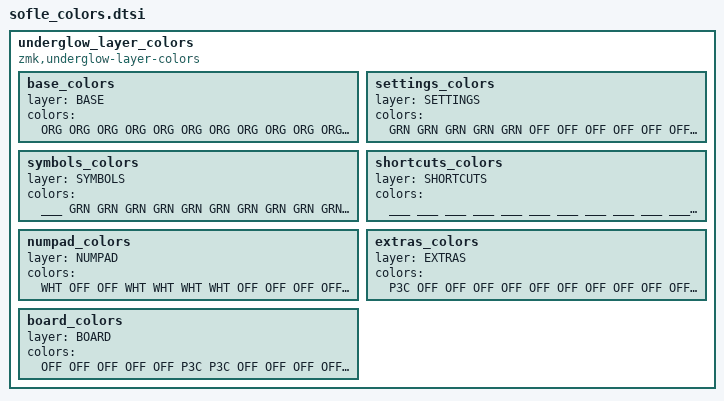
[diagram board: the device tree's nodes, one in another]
/*
 * Inclus dans sofle.keymap (à l'intérieur du nœud racine / { ... }).
 * Les noms de layers (BASE, SETTINGS...) sont définis dans sofle.keymap.
 */

/*
 * Couleurs par touche pour l'effet "couleurs par layer" (effet 4, fork ZMK
 * TheOnlyOneAkira/zmk branche sofle-layer-colors).
 * - Même disposition que les bindings du keymap (60 positions ; les deux
 *   emplacements des clics d'encodeur n'ont pas de LED, la valeur est ignorée).
 * - Le layer actif le plus haut qui définit une couleur l'emporte ;
 *   ___ (RGB_TRANS) laisse voir la couleur du layer en dessous.
 * - Une touche sans couleur sur aucun layer actif reste éteinte.
 * - Couleurs en 0xRRGGBB ; la luminosité globale (RGB_BRI / RGB_BRD) s'applique.
 *   La teinte (RGB_HUI, &rgb_p1...) n'a pas d'effet sur cet effet.
 */
#define ___ RGB_TRANS
#define OFF 0x000000
#define WHT 0xFFFFFF
#define RED 0xFF0000
#define GRN 0x00FF00
#define BLU 0x0000FF
#define CYN 0x00FFFF
#define PUR 0x8000FF
#define ORG 0xFF6000
#define YEL 0xFFC000
// Aperçu des presets &rgb_p1 ... &rgb_p5 (layer NUMPAD)
#define P1C 0xFF2A00
#define P2C 0xFFD400
#define P3C 0x00FFAA
#define P4C 0xD400FF
#define P5C 0x330800

    underglow_layer_colors {
        compatible = "zmk,underglow-layer-colors";

        base_colors {
            layer = <BASE>;
            colors = <
ORG ORG ORG ORG ORG ORG         ORG ORG ORG ORG ORG ORG
ORG ORG ORG ORG ORG ORG         ORG ORG ORG ORG ORG ORG
ORG ORG ORG ORG ORG ORG         ORG ORG ORG ORG ORG ORG
ORG ORG ORG ORG ORG ORG ___ ___ ORG ORG ORG ORG ORG ORG
        ORG ORG CYN ORG ORG ORG ORG GRN ORG ORG
            >;
        };

        // Bleu : sélection BT, cyan : déconnexion BT, rouge : BT_CLR, blanc : médias
        settings_colors {
            layer = <SETTINGS>;
            colors = <
GRN GRN GRN GRN GRN OFF         OFF OFF OFF OFF OFF OFF
ORG ORG ORG ORG ORG OFF         OFF OFF P2C OFF OFF OFF
___ OFF OFF OFF OFF OFF         OFF P2C P2C P2C OFF OFF
RED OFF OFF OFF OFF OFF OFF OFF OFF OFF OFF OFF ___ ___
        ___ ___ ___ ___ ___ ___ ___ ___ ___ ___
            >;
        };

        // Vert : F1-F12 et symboles, violet : accès au layer EXTRAS
        symbols_colors {
            layer = <SYMBOLS>;
            colors = <
___ GRN GRN GRN GRN GRN         GRN GRN GRN GRN GRN GRN
___ OFF OFF OFF OFF OFF         GRN GRN GRN GRN GRN GRN
___ OFF OFF OFF OFF OFF         GRN GRN GRN GRN GRN ___
___ OFF OFF GRN GRN GRN ___ ___ GRN GRN GRN OFF GRN ___
        OFF OFF P4C OFF ___ ___ ___ ___ CYN ___
            >;
        };

        // Jaune : raccourcis et navigation, blanc : flèches, violet : accès au layer EXTRAS
        shortcuts_colors {
            layer = <SHORTCUTS>;
            colors = <
___ ___ ___ ___ ___ ___         ___ ___ ___ ___ ___ CYN
___ CYN CYN CYN OFF CYN         CYN CYN CYN CYN ___ CYN
___ OFF OFF OFF OFF OFF         CYN CYN CYN CYN CYN CYN
OFF CYN CYN CYN CYN OFF ___ ___ OFF CYN OFF CYN CYN CYN
        ___ GRN ___ ___ ___ ___ ___ P4C ___ ___
            >;
        };

        // Cyan : réglages RGB, presets dans leur couleur, blanc : chiffres, orange : opérateurs
        numpad_colors {
            layer = <NUMPAD>;
            colors = <
WHT OFF OFF WHT WHT WHT         WHT OFF OFF OFF OFF OFF
OFF OFF OFF WHT WHT WHT         WHT WHT WHT WHT OFF WHT
WHT OFF OFF WHT WHT WHT         WHT WHT WHT WHT OFF OFF
WHT OFF OFF OFF OFF OFF ___ ___ WHT WHT WHT WHT OFF OFF
        WHT WHT WHT WHT WHT WHT WHT WHT WHT WHT
            >;
        };

        // Violet : changement de bureau et ext_power, rouge : accès au layer BOARD
        extras_colors {
            layer = <EXTRAS>;
            colors = <
P3C OFF OFF OFF OFF OFF         OFF OFF OFF OFF OFF P3C
OFF OFF OFF OFF OFF OFF         OFF OFF OFF OFF OFF OFF
OFF OFF OFF OFF OFF OFF         OFF P4C OFF P4C OFF OFF
OFF OFF OFF OFF OFF OFF OFF OFF OFF OFF OFF OFF OFF OFF
        OFF OFF OFF OFF P4C P4C OFF OFF OFF OFF
            >;
        };

        // Rouge : bootloader, orange : reset
        board_colors {
            layer = <BOARD>;
            colors = <
OFF OFF OFF OFF OFF P3C         P3C OFF OFF OFF OFF OFF
OFF OFF OFF OFF OFF P3C         P3C OFF OFF OFF OFF OFF
OFF OFF OFF OFF OFF OFF         OFF OFF OFF OFF OFF OFF
OFF OFF OFF OFF OFF OFF OFF OFF OFF OFF OFF OFF OFF OFF
        OFF OFF OFF OFF OFF OFF OFF OFF OFF OFF
            >;
        };
    };
